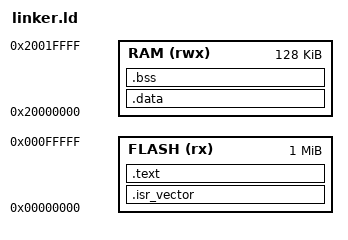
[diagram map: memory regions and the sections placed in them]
ENTRY(Reset_Handler)

MEMORY
{
    FLASH (rx)  : ORIGIN = 0x00000000, LENGTH = 1M
    RAM (rwx)   : ORIGIN = 0x20000000, LENGTH = 128K
}

_estack = ORIGIN(RAM) + LENGTH(RAM);

SECTIONS
{
    .isr_vector :
    {
        . = ALIGN(4);
        KEEP(*(.isr_vector))
        . = ALIGN(4);
    } > FLASH

    .text :
    {
        . = ALIGN(4);
        *(.text*)
        *(.init)
        *(.fini)
        *(.ARM.extab* .gnu.linkonce.armextab.*)
        *(.ARM.exidx* .gnu.linkonce.armexidx.*)
        *(.rodata*)
        . = ALIGN(4);
        _etext = .;
    } > FLASH

    .data : AT (_etext)
    {
        . = ALIGN(4);
        _sdata = .;
        *(.data*)
        . = ALIGN(4);
        _edata = .;
    } > RAM

    .bss :
    {
        . = ALIGN(4);
        _sbss = .;
        *(.bss*)
        *(COMMON)
        . = ALIGN(4);
        _ebss = .;
    } > RAM

    /DISCARD/ :
    {
        *(.note.GNU-stack)
        *(.comment)
    }
}
